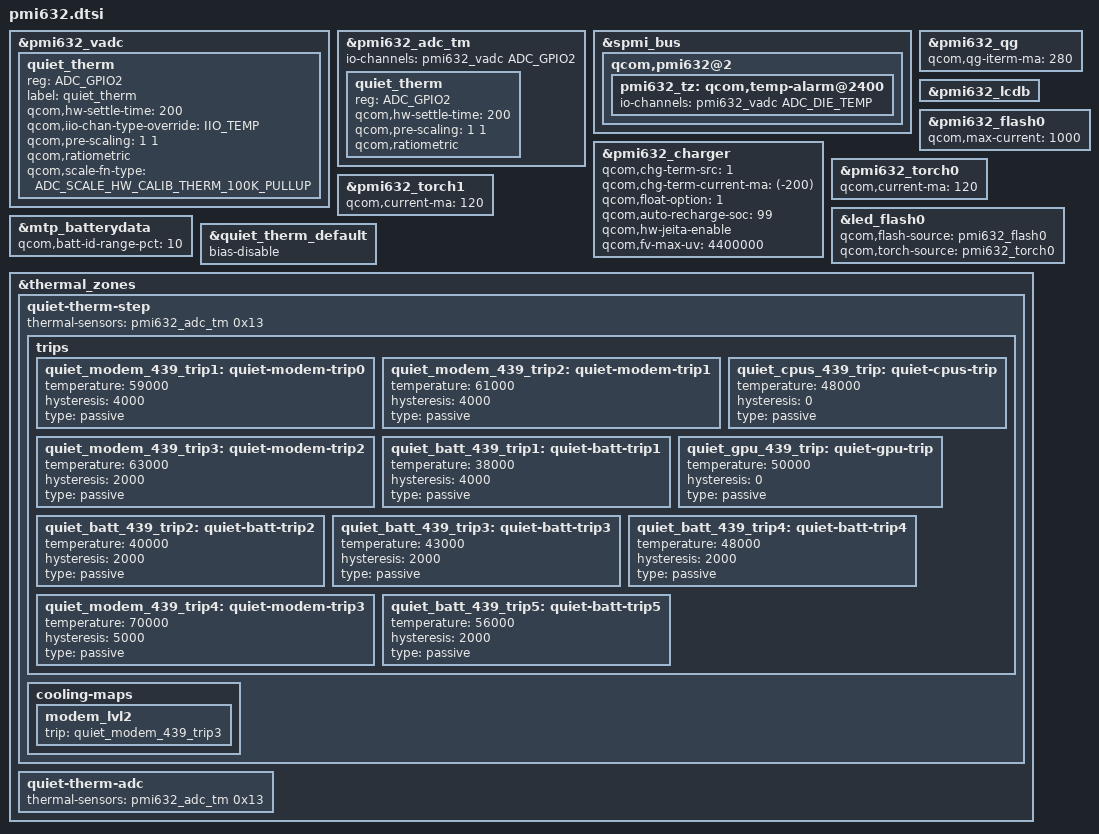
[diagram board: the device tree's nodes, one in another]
/* From stock pmi632.dtsi */
&pmi632_vadc {
	quiet_therm {
		reg = <ADC_GPIO2>;
		label = "quiet_therm";
		qcom,hw-settle-time = <200>;
		qcom,iio-chan-type-override = "IIO_TEMP";
		qcom,pre-scaling = <1 1>;
		qcom,ratiometric;
		qcom,scale-fn-type = <ADC_SCALE_HW_CALIB_THERM_100K_PULLUP>;
	};
};

&pmi632_adc_tm {
	io-channels = <&pmi632_vadc ADC_GPIO2>;

	quiet_therm {
		reg = <ADC_GPIO2>;
		qcom,hw-settle-time = <200>;
		qcom,pre-scaling = <1 1>;
		qcom,ratiometric;
	};
};

&spmi_bus {
	qcom,pmi632@2 {
		pmi632_tz: qcom,temp-alarm@2400 {
			io-channels = <&pmi632_vadc ADC_DIE_TEMP>;
			io-channel-names = "thermal";
		};
	};
};

&pmi632_charger {
	qcom,chg-term-src = <1>;
	qcom,chg-term-current-ma = <(-200)>;
	qcom,float-option = <1>;
	qcom,auto-recharge-soc = <99>;
	/delete-property/ qcom,sw-jeita-enable;
	qcom,hw-jeita-enable;
	qcom,fv-max-uv = <4400000>;
};

&pmi632_qg {
	qcom,qg-iterm-ma = <280>;
};

&pmi632_lcdb {
	/delete-property/ qcom,voltage-step-ramp;
};

&pmi632_flash0 {
	qcom,max-current = <1000>;
};

&pmi632_torch0 {
	qcom,current-ma = <120>;
};

&pmi632_torch1 {
	qcom,current-ma = <120>;
};

&led_flash0 {
	qcom,flash-source = <&pmi632_flash0>;
	qcom,torch-source = <&pmi632_torch0>;
};

/* From stock sdm439-pmi632.dtsi */
&mtp_batterydata {
	qcom,batt-id-range-pct = <10>;
	/delete-node/ qcom,ascent_3450mah;
	/delete-node/ qcom,mlp356477_2800mah;
	#include "batterydata/Peony-GY-4000mah-51kohm.dtsi"
	#include "batterydata/Peony-NVT-4000mah-41kohm.dtsi"
	#include "batterydata/Peony-SWD-4000mah-78kohm.dtsi"
	#include "batterydata/Peony-Default-4000mah-78kohm.dtsi"
};

&quiet_therm_default {
	bias-disable;
};

&thermal_zones {
	quiet-therm-step {
		thermal-sensors = <&pmi632_adc_tm 0x13>;
		/delete-property/ wake-capable-sensor;
		/delete-node/ trips;
		trips {
			/* Note: A lot has changed, just redefine the node here */
			quiet_modem_439_trip1: quiet-modem-trip0 {
				temperature = <59000>;
				hysteresis = <4000>;
				type = "passive";
			};
			quiet_modem_439_trip2: quiet-modem-trip1 {
				temperature = <61000>;
				hysteresis = <4000>;
				type = "passive";
			};
			quiet_cpus_439_trip: quiet-cpus-trip {
				temperature = <48000>;
				hysteresis = <0>;
				type = "passive";
			};
			quiet_modem_439_trip3: quiet-modem-trip2 {
				temperature = <63000>;
				hysteresis = <2000>;
				type = "passive";
			};
			quiet_batt_439_trip1: quiet-batt-trip1 {
				temperature = <38000>;
				hysteresis = <4000>;
				type = "passive";
			};
			quiet_gpu_439_trip: quiet-gpu-trip {
				temperature = <50000>;
				hysteresis = <0>;
				type = "passive";
			};
			quiet_batt_439_trip2: quiet-batt-trip2 {
				temperature = <40000>;
				hysteresis = <2000>;
				type = "passive";
			};
			quiet_batt_439_trip3: quiet-batt-trip3 {
				temperature = <43000>;
				hysteresis = <2000>;
				type = "passive";
			};
			quiet_batt_439_trip4: quiet-batt-trip4 {
				temperature = <48000>;
				hysteresis = <2000>;
				type = "passive";
			};
			quiet_modem_439_trip4: quiet-modem-trip3 {
				temperature = <70000>;
				hysteresis = <5000>;
				type = "passive";
			};
			quiet_batt_439_trip5: quiet-batt-trip5 {
				temperature = <56000>;
				hysteresis = <2000>;
				type = "passive";
			};
		};
		cooling-maps {
			modem_lvl2 {
				trip = <&quiet_modem_439_trip3>;
			};
			/delete-node/ battery_lvl6;
			/delete-node/ battery_lvl7;
		};
	};

	quiet-therm-adc {
		thermal-sensors = <&pmi632_adc_tm 0x13>;
		/delete-property/ wake-capable-sensor;
	};
};
